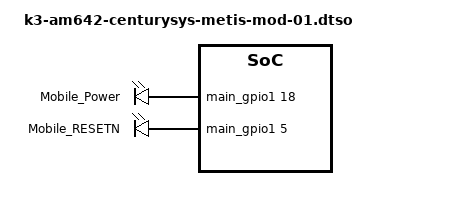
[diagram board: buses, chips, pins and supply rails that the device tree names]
// SPDX-License-Identifier: GPL-2.0
/**
 * DT overlay for LTE module (Module Code: 0x01)
 *
 * Copyright (C) 2022 Century Systems
 */

/dts-v1/;
/plugin/;
#include <dt-bindings/gpio/gpio.h>
#include <dt-bindings/interrupt-controller/irq.h>
#include "k3-pinctrl.h"

&leds {
	mobile_power {
		label = "Mobile_Power";
		gpios = <&main_gpio1 18 GPIO_ACTIVE_HIGH>;
		default-state = "on";
	};

	mobile_reset {
		label = "Mobile_RESETN";
		gpios = <&main_gpio1 5 GPIO_ACTIVE_HIGH>;
		linux,default-trigger = "oneshot";
		led-pattern = <200 100>;
	};
};

&leds_msp430 {
	sim_select {
		label = "SIM_Sel";
		gpios = <&io_exp 7 GPIO_ACTIVE_HIGH>;
		retain-state-suspended;
		retain-state-shutdown;
		default-state = "keep";
	};
};
